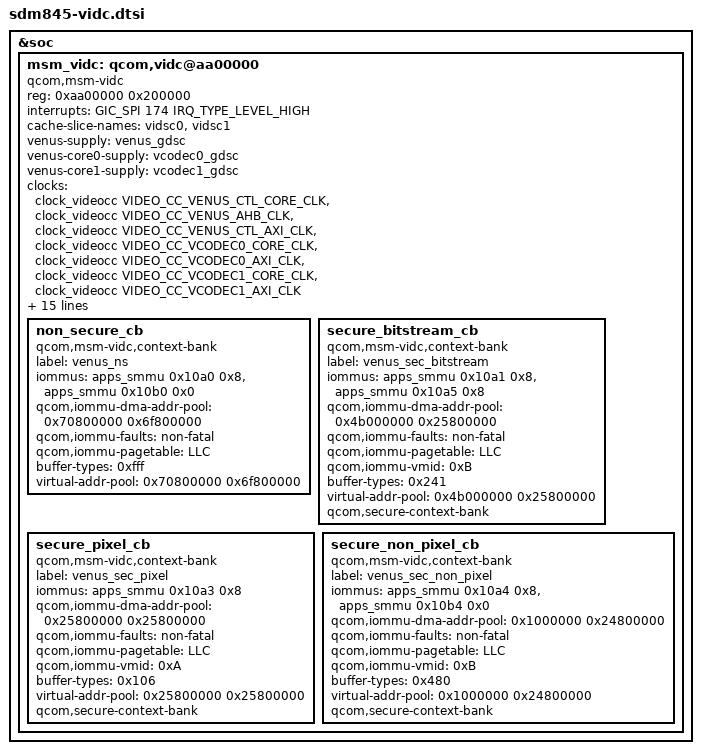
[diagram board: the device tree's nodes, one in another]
// SPDX-License-Identifier: GPL-2.0-only
/*
 * Copyright (c) 2017-2018, The Linux Foundation. All rights reserved.
 * Copyright (c) 2021, 2025, Pavel Dubrova <pashadubrova@gmail.com>
 */

#include <dt-bindings/interrupt-controller/arm-gic.h>
#include <dt-bindings/clock/qcom,videocc-sdm845.h>

&soc {
	msm_vidc: qcom,vidc@aa00000 {
		compatible = "qcom,msm-vidc", "qcom,sdm845-vidc";
		status = "ok";
		reg = <0xaa00000 0x200000>;
		interrupts = <GIC_SPI 174 IRQ_TYPE_LEVEL_HIGH>;

		/* LLCC Info */
		cache-slice-names = "vidsc0", "vidsc1";

		/* Supply */
		venus-supply = <&venus_gdsc>;
		venus-core0-supply = <&vcodec0_gdsc>;
		venus-core1-supply = <&vcodec1_gdsc>;

		/* Clocks */
		clock-names = "core_clk", "iface_clk", "bus_clk",
			"core0_clk", "core0_bus_clk",
			"core1_clk", "core1_bus_clk";
		clocks = <&clock_videocc VIDEO_CC_VENUS_CTL_CORE_CLK>,
			<&clock_videocc VIDEO_CC_VENUS_AHB_CLK>,
			<&clock_videocc VIDEO_CC_VENUS_CTL_AXI_CLK>,
			<&clock_videocc VIDEO_CC_VCODEC0_CORE_CLK>,
			<&clock_videocc VIDEO_CC_VCODEC0_AXI_CLK>,
			<&clock_videocc VIDEO_CC_VCODEC1_CORE_CLK>,
			<&clock_videocc VIDEO_CC_VCODEC1_AXI_CLK>;
		qcom,proxy-clock-names = "core_clk", "iface_clk",
			"bus_clk", "core0_clk", "core0_bus_clk",
			"core1_clk", "core1_bus_clk";
		qcom,clock-configs = <0x1 0x0 0x0 0x1 0x0 0x1 0x0>;
		qcom,allowed-clock-rates = <100000000 200000000 320000000
			380000000 444000000 533000000>;

		/* Buse Interconnects */
		interconnect-names = "venus-cnoc", "venus-ddr", "venus-arm9-ddr", "venus-llcc";
		interconnects =
			<&gladiator_noc MASTER_AMPSS_M0 &config_noc SLAVE_VENUS_CFG>,
			<&mc_virt MASTER_LLCC &mc_virt SLAVE_EBI1>,
			<&mmss_noc MASTER_VIDEO_P0 &mc_virt SLAVE_EBI1>,
			<&mmss_noc MASTER_VIDEO_P0 &mem_noc SLAVE_LLCC>;

		/* Bus BW range (low, high) for each bus */
		qcom,bus-range-kbps = <1000 1000
			1000 3388000
			1000 1000
			17000 3388000>;

		/* MMUs */
		non_secure_cb {
			compatible = "qcom,msm-vidc,context-bank";
			label = "venus_ns";
			iommus =
				<&apps_smmu 0x10a0 0x8>,
				<&apps_smmu 0x10b0 0x0>;
			qcom,iommu-dma-addr-pool = <0x70800000 0x6f800000>;
			qcom,iommu-faults = "non-fatal";
			qcom,iommu-pagetable = "LLC";
			buffer-types = <0xfff>;
			virtual-addr-pool = <0x70800000 0x6f800000>;
		};

		secure_bitstream_cb {
			compatible = "qcom,msm-vidc,context-bank";
			label = "venus_sec_bitstream";
			iommus =
				<&apps_smmu 0x10a1 0x8>,
				<&apps_smmu 0x10a5 0x8>;
			qcom,iommu-dma-addr-pool = <0x4b000000 0x25800000>;
			qcom,iommu-faults = "non-fatal";
			qcom,iommu-pagetable = "LLC";
			qcom,iommu-vmid = <0xB>; /* VMID_CP_BITSTREAM */
			buffer-types = <0x241>;
			virtual-addr-pool = <0x4b000000 0x25800000>;
			qcom,secure-context-bank;
		};

		secure_pixel_cb {
			compatible = "qcom,msm-vidc,context-bank";
			label = "venus_sec_pixel";
			iommus =
				<&apps_smmu 0x10a3 0x8>;
			qcom,iommu-dma-addr-pool = <0x25800000 0x25800000>;
			qcom,iommu-faults = "non-fatal";
			qcom,iommu-pagetable = "LLC";
			qcom,iommu-vmid = <0xA>; /* VMID_CP_PIXEL */
			buffer-types = <0x106>;
			virtual-addr-pool = <0x25800000 0x25800000>;
			qcom,secure-context-bank;
		};

		secure_non_pixel_cb {
			compatible = "qcom,msm-vidc,context-bank";
			label = "venus_sec_non_pixel";
			iommus =
				<&apps_smmu 0x10a4 0x8>,
				<&apps_smmu 0x10b4 0x0>;
			qcom,iommu-dma-addr-pool = <0x1000000 0x24800000>;
			qcom,iommu-faults = "non-fatal";
			qcom,iommu-pagetable = "LLC";
			qcom,iommu-vmid = <0xB>; /* VMID_CP_NON_PIXEL */
			buffer-types = <0x480>;
			virtual-addr-pool = <0x1000000 0x24800000>;
			qcom,secure-context-bank;
		};
	};
};
